# MAIN_CTRL_MMR_MAIN_CTRL_MMR_CFG0_00100000h register map
Vendor: Texas Instruments
Registers are 32-bit, read-write, reset 0x0 unless marked. A register's access mark holds for its fields unless they carry their own. Offsets are as the file gives them; [hi:lo] are bit positions; {n}, {i} and the like mark numbered series.

## MAIN_CTRL_MMR_CFG0 (part 2 of 2)
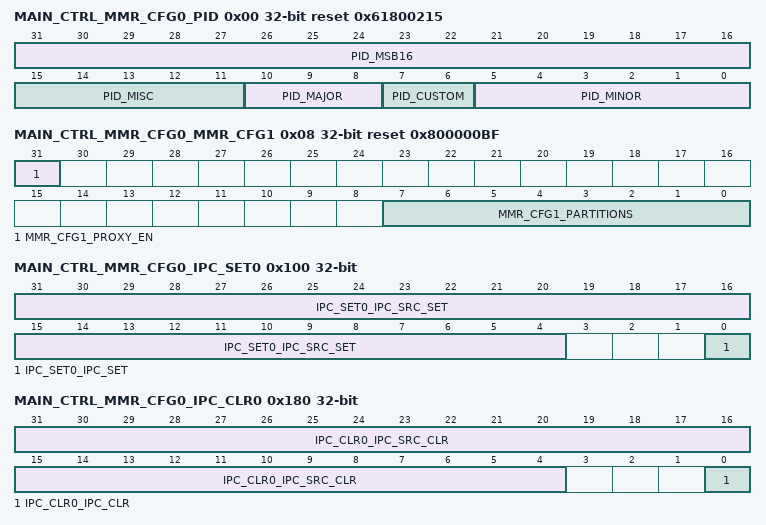
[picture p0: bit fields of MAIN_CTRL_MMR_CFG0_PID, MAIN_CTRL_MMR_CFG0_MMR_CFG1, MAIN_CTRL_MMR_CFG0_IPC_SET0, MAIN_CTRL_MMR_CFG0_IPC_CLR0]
0x00 MAIN_CTRL_MMR_CFG0_PID ro reset 0x61800215
  [31:16] PID_MSB16 — Reset Source: mod_g_rst_n
  [15:11] PID_MISC — Reset Source: mod_g_rst_n
  [10:8] PID_MAJOR — Reset Source: mod_g_rst_n
  [7:6] PID_CUSTOM — Reset Source: mod_g_rst_n
  [5:0] PID_MINOR — Reset Source: mod_g_rst_n
0x08 MAIN_CTRL_MMR_CFG0_MMR_CFG1 ro reset 0x800000BF
  [31] MMR_CFG1_PROXY_EN — Proxy addressing activated Reset Source: mod_por_rst_n
  [7:0] MMR_CFG1_PARTITIONS — Indicates present partitions Reset Source: mod_por_rst_n
0x100 MAIN_CTRL_MMR_CFG0_IPC_SET0 access not given
  [31:4] IPC_SET0_IPC_SRC_SET — Read returns current valueWrite: 0 - No effect 1 - Sets both corresponding IPC_CLR and the IPC_SET bits Reset Source: mod_g_rst_n (access R/W1TS)
  [0] IPC_SET0_IPC_SET — Read returns 0Write: 0 - No effect 1 - Sets both corresponding IPC_CLR and the IPC_SET bits Reset Source: mod_g_rst_n (access R/W1TS)
0x180 MAIN_CTRL_MMR_CFG0_IPC_CLR0 access not given
  [31:4] IPC_CLR0_IPC_SRC_CLR — Read returns current valueWrite: 0 - No effect 1 - Clears both corresponding IPC_CLR and the IPC_SET bits Reset Source: mod_g_rst_n (access R/W1TC)
  [0] IPC_CLR0_IPC_CLR — Read returns current valueWrite: 0 - No effect 1 - Clears both corresponding IPC_CLR and the IPC_SET bits Reset Source: mod_g_rst_n (access R/W1TC)
{0x1008+0x4000*i} MAIN_CTRL_MMR_CFG0_LOCK{i}_KICK0 (i=0..2)
  [31:0] LOCK{i}_KICK0 — - KICK0 component Reset Source: mod_g_rst_n
{0x100C+0x4000*i} MAIN_CTRL_MMR_CFG0_LOCK{i}_KICK1 (i=0..2)
  [31:0] LOCK{i}_KICK1 — - KICK1 component Reset Source: mod_g_rst_n
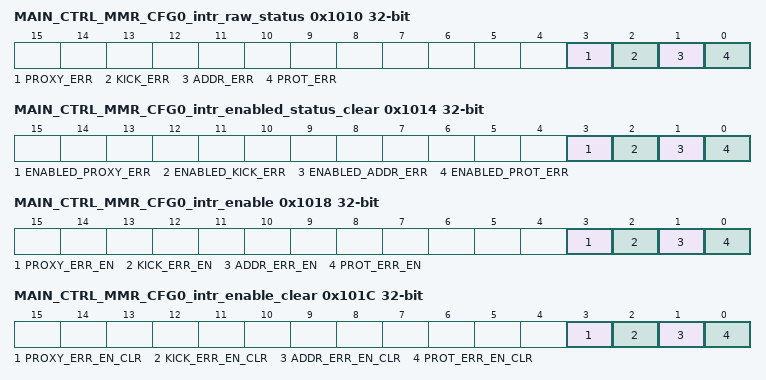
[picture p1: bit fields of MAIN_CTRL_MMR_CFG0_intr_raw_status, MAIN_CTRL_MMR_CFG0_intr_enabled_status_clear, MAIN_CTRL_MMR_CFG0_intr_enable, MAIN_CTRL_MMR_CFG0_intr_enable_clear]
0x1010 MAIN_CTRL_MMR_CFG0_intr_raw_status access not given
  [3] PROXY_ERR — Proxy0 access violation error. Raw status is read. Write a 1 to set the status. Writing a 0 has no effect. Reset Source: mod_g_rst_n (access R/W1TS)
  [2] KICK_ERR — Kick access violation error. Raw status is read. Write a 1 to set the status. Writing a 0 has no effect. Reset Source: mod_g_rst_n (access R/W1TS)
  [1] ADDR_ERR — Addressing violation error. Raw status is read. Write a 1 to set the status. Writing a 0 has no effect. Reset Source: mod_g_rst_n (access R/W1TS)
  [0] PROT_ERR — Protection violation error. Raw status is read. Write a 1 to set the status. Writing a 0 has no effect. Reset Source: mod_g_rst_n (access R/W1TS)
0x1014 MAIN_CTRL_MMR_CFG0_intr_enabled_status_clear access not given
  [3] ENABLED_PROXY_ERR — Proxy0 access violation error. Enabled status is read. Write a 1 to clear the status. Writing a 0 has no effect. Reset Source: mod_g_rst_n (access R/W1TC)
  [2] ENABLED_KICK_ERR — Kick access violation error. Enabled status is read. Write a 1 to clear the status. Writing a 0 has no effect. Reset Source: mod_g_rst_n (access R/W1TC)
  [1] ENABLED_ADDR_ERR — Addressing violation error. Enabled status is read. Write a 1 to clear the status. Writing a 0 has no effect. Reset Source: mod_g_rst_n (access R/W1TC)
  [0] ENABLED_PROT_ERR — Protection violation error. Enabled status is read. Write a 1 to clear the status. Writing a 0 has no effect. Reset Source: mod_g_rst_n (access R/W1TC)
0x1018 MAIN_CTRL_MMR_CFG0_intr_enable access not given
  [3] PROXY_ERR_EN — Proxy0 access violation error enable. Write a 1 to set the enable. Writing a 0 has no effect. Reset Source: mod_g_rst_n (access R/W1TS)
  [2] KICK_ERR_EN — Kick access violation error enable. Write a 1 to set the enable. Writing a 0 has no effect. Reset Source: mod_g_rst_n (access R/W1TS)
  [1] ADDR_ERR_EN — Addressing violation error enable. Write a 1 to set the enable. Writing a 0 has no effect. Reset Source: mod_g_rst_n (access R/W1TS)
  [0] PROT_ERR_EN — Protection violation error enable. Write a 1 to set the enable. Writing a 0 has no effect. Reset Source: mod_g_rst_n (access R/W1TS)
0x101C MAIN_CTRL_MMR_CFG0_intr_enable_clear access not given
  [3] PROXY_ERR_EN_CLR — Proxy0 access violation error enable clear. Write a 1 to clear the enable. Writing a 0 has no effect. Reset Source: mod_g_rst_n (access R/W1TC)
  [2] KICK_ERR_EN_CLR — Kick access violation error enable clear. Write a 1 to clear the enable. Writing a 0 has no effect. Reset Source: mod_g_rst_n (access R/W1TC)
  [1] ADDR_ERR_EN_CLR — Addressing violation error enable clear. Write a 1 to clear the enable. Writing a 0 has no effect. Reset Source: mod_g_rst_n (access R/W1TC)
  [0] PROT_ERR_EN_CLR — Protection violation error enable clear. Write a 1 to clear the enable. Writing a 0 has no effect. Reset Source: mod_g_rst_n (access R/W1TC)
0x1020 MAIN_CTRL_MMR_CFG0_eoi
  [7:0] EOI_VECTOR — EOI vector value. Write this with interrupt distribution value in the chip. Reset Source: mod_g_rst_n
0x1024 MAIN_CTRL_MMR_CFG0_fault_address ro
  [31:0] FAULT_ADDR — Fault Address. Reset Source: mod_g_rst_n
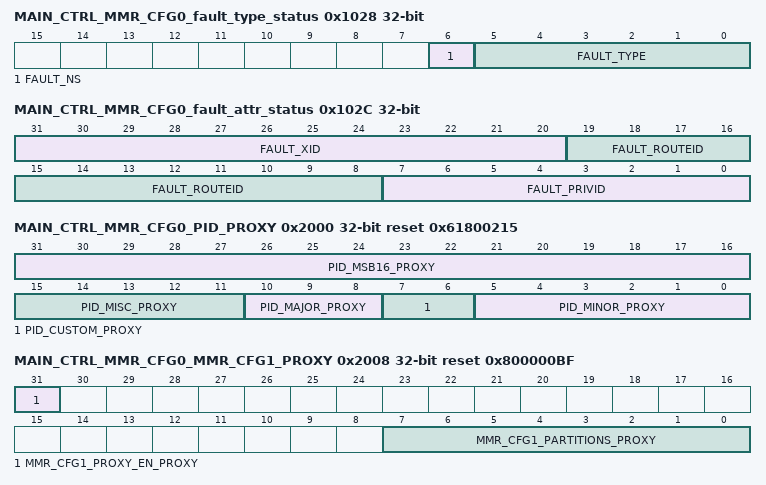
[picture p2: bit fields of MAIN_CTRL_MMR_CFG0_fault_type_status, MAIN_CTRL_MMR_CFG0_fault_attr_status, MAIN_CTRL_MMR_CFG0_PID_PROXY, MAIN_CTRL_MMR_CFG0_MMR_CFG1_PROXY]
0x1028 MAIN_CTRL_MMR_CFG0_fault_type_status ro
  [6] FAULT_NS — Non-secure access. Reset Source: mod_g_rst_n
  [5:0] FAULT_TYPE — Fault Type 10_0000 = Supervisor read fault - priv = 1 dir = 1 dtype != 1 01_0000 = Supervisor write fault - priv = 1 dir = 0 00_1000 = Supervisor execute fault - priv = 1 dir = 1 dtype = 1 00_0100 = User read fault - priv = 0 dir = 1 dtype = 1 00_0010 = User write fault - priv = 0 dir = 0 00_0001 = User execute fault - priv = 0 dir = 1 dtype = 1 00_0000 = No fault Reset Source: mod_g_rst_n
0x102C MAIN_CTRL_MMR_CFG0_fault_attr_status ro
  [31:20] FAULT_XID — XID. Reset Source: mod_g_rst_n
  [19:8] FAULT_ROUTEID — Route ID. Reset Source: mod_g_rst_n
  [7:0] FAULT_PRIVID — Privilege ID. Reset Source: mod_g_rst_n
0x1030 MAIN_CTRL_MMR_CFG0_fault_clear wo
  [0] FAULT_CLR — Fault clear. Writing a 1 clears the current fault. Writing a 0 has no effect. Reset Source: mod_g_rst_n
{0x1100+4i} MAIN_CTRL_MMR_CFG0_CLAIMREG_P0_R{i}_READONLY ro (i=0..6)
  [31:0] CLAIMREG_P0_R{i}_READONLY — Claim bits for Partition 0 Reset Source: mod_g_rst_n
0x2000 MAIN_CTRL_MMR_CFG0_PID_PROXY ro reset 0x61800215
  [31:16] PID_MSB16_PROXY — Reset Source: mod_g_rst_n
  [15:11] PID_MISC_PROXY — Reset Source: mod_g_rst_n
  [10:8] PID_MAJOR_PROXY — Reset Source: mod_g_rst_n
  [7:6] PID_CUSTOM_PROXY — Reset Source: mod_g_rst_n
  [5:0] PID_MINOR_PROXY — Reset Source: mod_g_rst_n
0x2008 MAIN_CTRL_MMR_CFG0_MMR_CFG1_PROXY ro reset 0x800000BF
  [31] MMR_CFG1_PROXY_EN_PROXY — Proxy addressing activated Reset Source: mod_por_rst_n
  [7:0] MMR_CFG1_PARTITIONS_PROXY — Indicates present partitions Reset Source: mod_por_rst_n
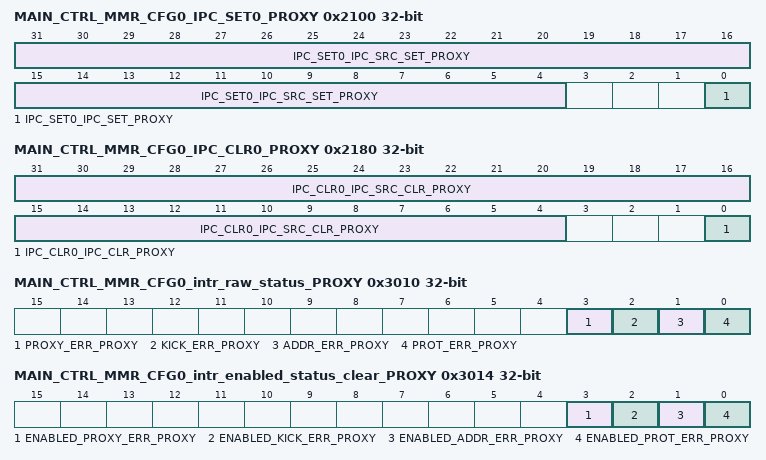
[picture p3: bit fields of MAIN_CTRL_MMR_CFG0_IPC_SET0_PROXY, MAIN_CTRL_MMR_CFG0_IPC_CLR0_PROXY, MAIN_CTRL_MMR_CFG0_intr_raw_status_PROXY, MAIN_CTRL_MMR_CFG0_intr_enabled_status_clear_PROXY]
0x2100 MAIN_CTRL_MMR_CFG0_IPC_SET0_PROXY access not given
  [31:4] IPC_SET0_IPC_SRC_SET_PROXY — Read returns current valueWrite: 0 - No effect 1 - Sets both corresponding IPC_CLR and the IPC_SET bits Reset Source: mod_g_rst_n (access R/W1TS)
  [0] IPC_SET0_IPC_SET_PROXY — Read returns 0Write: 0 - No effect 1 - Sets both corresponding IPC_CLR and the IPC_SET bits Reset Source: mod_g_rst_n (access R/W1TS)
0x2180 MAIN_CTRL_MMR_CFG0_IPC_CLR0_PROXY access not given
  [31:4] IPC_CLR0_IPC_SRC_CLR_PROXY — Read returns current valueWrite: 0 - No effect 1 - Clears both corresponding IPC_CLR and the IPC_SET bits Reset Source: mod_g_rst_n (access R/W1TC)
  [0] IPC_CLR0_IPC_CLR_PROXY — Read returns current valueWrite: 0 - No effect 1 - Clears both corresponding IPC_CLR and the IPC_SET bits Reset Source: mod_g_rst_n (access R/W1TC)
{0x3008+0x4000*i} MAIN_CTRL_MMR_CFG0_LOCK{i}_KICK0_PROXY (i=0..2)
  [31:0] LOCK{i}_KICK0_PROXY — - KICK0 component Reset Source: mod_g_rst_n
{0x300C+0x4000*i} MAIN_CTRL_MMR_CFG0_LOCK{i}_KICK1_PROXY (i=0..2)
  [31:0] LOCK{i}_KICK1_PROXY — - KICK1 component Reset Source: mod_g_rst_n
0x3010 MAIN_CTRL_MMR_CFG0_intr_raw_status_PROXY access not given
  [3] PROXY_ERR_PROXY — Proxy0 access violation error. Raw status is read. Write a 1 to set the status. Writing a 0 has no effect. Reset Source: mod_g_rst_n (access R/W1TS)
  [2] KICK_ERR_PROXY — Kick access violation error. Raw status is read. Write a 1 to set the status. Writing a 0 has no effect. Reset Source: mod_g_rst_n (access R/W1TS)
  [1] ADDR_ERR_PROXY — Addressing violation error. Raw status is read. Write a 1 to set the status. Writing a 0 has no effect. Reset Source: mod_g_rst_n (access R/W1TS)
  [0] PROT_ERR_PROXY — Protection violation error. Raw status is read. Write a 1 to set the status. Writing a 0 has no effect. Reset Source: mod_g_rst_n (access R/W1TS)
0x3014 MAIN_CTRL_MMR_CFG0_intr_enabled_status_clear_PROXY access not given
  [3] ENABLED_PROXY_ERR_PROXY — Proxy0 access violation error. Enabled status is read. Write a 1 to clear the status. Writing a 0 has no effect. Reset Source: mod_g_rst_n (access R/W1TC)
  [2] ENABLED_KICK_ERR_PROXY — Kick access violation error. Enabled status is read. Write a 1 to clear the status. Writing a 0 has no effect. Reset Source: mod_g_rst_n (access R/W1TC)
  [1] ENABLED_ADDR_ERR_PROXY — Addressing violation error. Enabled status is read. Write a 1 to clear the status. Writing a 0 has no effect. Reset Source: mod_g_rst_n (access R/W1TC)
  [0] ENABLED_PROT_ERR_PROXY — Protection violation error. Enabled status is read. Write a 1 to clear the status. Writing a 0 has no effect. Reset Source: mod_g_rst_n (access R/W1TC)
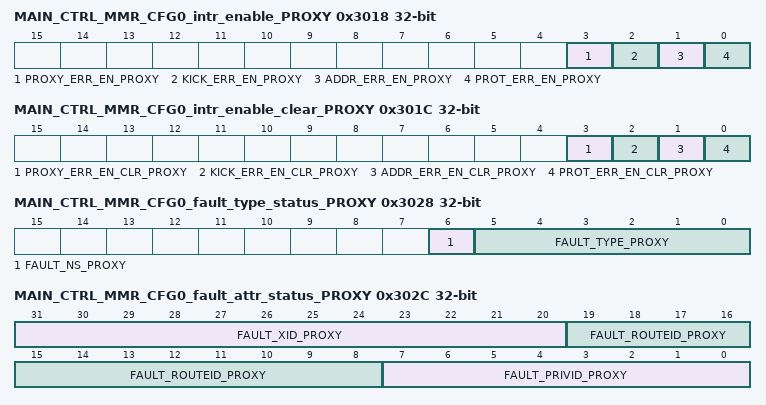
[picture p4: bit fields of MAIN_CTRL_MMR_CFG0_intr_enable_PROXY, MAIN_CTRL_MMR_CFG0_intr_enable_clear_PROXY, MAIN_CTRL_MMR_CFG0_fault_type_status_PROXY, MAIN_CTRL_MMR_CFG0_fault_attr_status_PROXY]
0x3018 MAIN_CTRL_MMR_CFG0_intr_enable_PROXY access not given
  [3] PROXY_ERR_EN_PROXY — Proxy0 access violation error enable. Write a 1 to set the enable. Writing a 0 has no effect. Reset Source: mod_g_rst_n (access R/W1TS)
  [2] KICK_ERR_EN_PROXY — Kick access violation error enable. Write a 1 to set the enable. Writing a 0 has no effect. Reset Source: mod_g_rst_n (access R/W1TS)
  [1] ADDR_ERR_EN_PROXY — Addressing violation error enable. Write a 1 to set the enable. Writing a 0 has no effect. Reset Source: mod_g_rst_n (access R/W1TS)
  [0] PROT_ERR_EN_PROXY — Protection violation error enable. Write a 1 to set the enable. Writing a 0 has no effect. Reset Source: mod_g_rst_n (access R/W1TS)
0x301C MAIN_CTRL_MMR_CFG0_intr_enable_clear_PROXY access not given
  [3] PROXY_ERR_EN_CLR_PROXY — Proxy0 access violation error enable clear. Write a 1 to clear the enable. Writing a 0 has no effect. Reset Source: mod_g_rst_n (access R/W1TC)
  [2] KICK_ERR_EN_CLR_PROXY — Kick access violation error enable clear. Write a 1 to clear the enable. Writing a 0 has no effect. Reset Source: mod_g_rst_n (access R/W1TC)
  [1] ADDR_ERR_EN_CLR_PROXY — Addressing violation error enable clear. Write a 1 to clear the enable. Writing a 0 has no effect. Reset Source: mod_g_rst_n (access R/W1TC)
  [0] PROT_ERR_EN_CLR_PROXY — Protection violation error enable clear. Write a 1 to clear the enable. Writing a 0 has no effect. Reset Source: mod_g_rst_n (access R/W1TC)
0x3020 MAIN_CTRL_MMR_CFG0_eoi_PROXY
  [7:0] EOI_VECTOR_PROXY — EOI vector value. Write this with interrupt distribution value in the chip. Reset Source: mod_g_rst_n
0x3024 MAIN_CTRL_MMR_CFG0_fault_address_PROXY ro
  [31:0] FAULT_ADDR_PROXY — Fault Address. Reset Source: mod_g_rst_n
0x3028 MAIN_CTRL_MMR_CFG0_fault_type_status_PROXY ro
  [6] FAULT_NS_PROXY — Non-secure access. Reset Source: mod_g_rst_n
  [5:0] FAULT_TYPE_PROXY — Fault Type 10_0000 = Supervisor read fault - priv = 1 dir = 1 dtype != 1 01_0000 = Supervisor write fault - priv = 1 dir = 0 00_1000 = Supervisor execute fault - priv = 1 dir = 1 dtype = 1 00_0100 = User read fault - priv = 0 dir = 1 dtype = 1 00_0010 = User write fault - priv = 0 dir = 0 00_0001 = User execute fault - priv = 0 dir = 1 dtype = 1 00_0000 = No fault Reset Source: mod_g_rst_n
0x302C MAIN_CTRL_MMR_CFG0_fault_attr_status_PROXY ro
  [31:20] FAULT_XID_PROXY — XID. Reset Source: mod_g_rst_n
  [19:8] FAULT_ROUTEID_PROXY — Route ID. Reset Source: mod_g_rst_n
  [7:0] FAULT_PRIVID_PROXY — Privilege ID. Reset Source: mod_g_rst_n
0x3030 MAIN_CTRL_MMR_CFG0_fault_clear_PROXY wo
  [0] FAULT_CLR_PROXY — Fault clear. Writing a 1 clears the current fault. Writing a 0 has no effect. Reset Source: mod_g_rst_n
{0x3100+4i} MAIN_CTRL_MMR_CFG0_CLAIMREG_P0_R{i} (i=0..6)
  [31:0] CLAIMREG_P0_R{i} — Claim bits for Partition 0 Reset Source: mod_g_rst_n
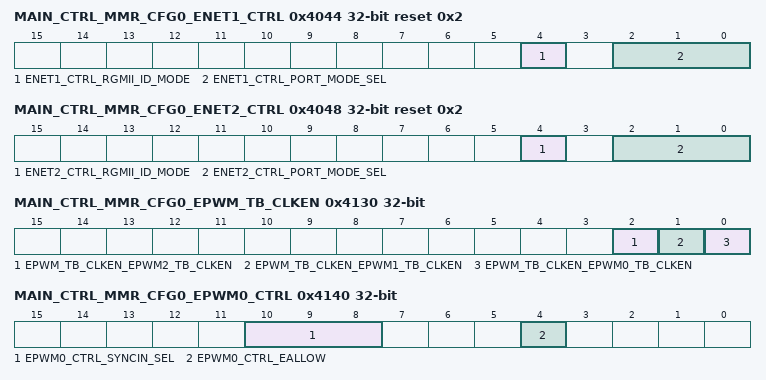
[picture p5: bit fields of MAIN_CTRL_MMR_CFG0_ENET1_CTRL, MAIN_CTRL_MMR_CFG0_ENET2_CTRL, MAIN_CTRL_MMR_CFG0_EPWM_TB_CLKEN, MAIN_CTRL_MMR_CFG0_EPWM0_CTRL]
0x4044 MAIN_CTRL_MMR_CFG0_ENET1_CTRL reset 0x2
  [4] ENET1_CTRL_RGMII_ID_MODE — Port1 RGMII internal transmit delay selection 0 - Internal transmit delay 1 - No intenal transmit delay Reset Source: sys_por_rst_n
  [2:0] ENET1_CTRL_PORT_MODE_SEL — Selects Ethernet switch Port1 interface Field values (others are reserved):3'b000 - GMII/MII (not supported)3'b001 - RMII3'b010 - RGMII3'b011 - SGMII (not supported)3'b100 - QSGMII (not supported)3'b101 - XFI (not supported)3'b110 - QSGMII_SUB (not supported)3'b111 - Reserved Reset Source: sys_por_rst_n
0x4048 MAIN_CTRL_MMR_CFG0_ENET2_CTRL reset 0x2
  [4] ENET2_CTRL_RGMII_ID_MODE — Port2 RGMII internal transmit delay selection 0 - Internal transmit delay 1 - No intenal transmit delay Reset Source: sys_por_rst_n
  [2:0] ENET2_CTRL_PORT_MODE_SEL — Selects Ethernet switch Port2 interface Field values (others are reserved):3'b000 - GMII/MII (not supported)3'b001 - RMII3'b010 - RGMII3'b011 - SGMII (not supported)3'b100 - QSGMII (not supported)3'b101 - XFI (not supported)3'b110 - QSGMII_SUB (not supported)3'b111 - Reserved Reset Source: sys_por_rst_n
0x4130 MAIN_CTRL_MMR_CFG0_EPWM_TB_CLKEN
  [2] EPWM_TB_CLKEN_EPWM2_TB_CLKEN — Activates Timebase Clock of EPWM2 When Set Reset Source: mod_g_rst_n
  [1] EPWM_TB_CLKEN_EPWM1_TB_CLKEN — Activates Timebase Clock of EPWM1 When Set Reset Source: mod_g_rst_n
  [0] EPWM_TB_CLKEN_EPWM0_TB_CLKEN — Activates Timebase Clock of EPWM0 When Set Reset Source: mod_g_rst_n
0x4140 MAIN_CTRL_MMR_CFG0_EPWM0_CTRL
  [10:8] EPWM0_CTRL_SYNCIN_SEL — Selects the source of the EPWM0 synchronization inputField values (others are reserved):3'b000 - EPWM0_SYNCIN Pin3'b001 - None3'b010 - Time Sync Router 193'b011 - Compare Event Router 32undefined - undefined3'b100 - None3'b101 - None3'b110 - None3'b111 - None Reset Source: mod_g_rst_n
  [4] EPWM0_CTRL_EALLOW — Activate write access to EPWM tripzone registers 0 - Deactivated 1 - Activated Reset Source: mod_g_rst_n
0x4144 MAIN_CTRL_MMR_CFG0_EPWM1_CTRL
  [4] EPWM1_CTRL_EALLOW — Activate write access to EPWM tripzone registers 0 - Deactivated 1 - Activated Reset Source: mod_g_rst_n
0x4148 MAIN_CTRL_MMR_CFG0_EPWM2_CTRL
  [4] EPWM2_CTRL_EALLOW — Activate write access to EPWM tripzone registers 0 - Deactivated 1 - Activated Reset Source: mod_g_rst_n
{0x4180+4i} MAIN_CTRL_MMR_CFG0_EQEP{i}_CTRL (i=0..2)
  [4:0] EQEP{i}_CTRL_SOCA_SEL — Selects the source of SOCA input for EQEP{i}Field values (others are reserved):undefined - undefinedundefined - undefined5'b00010 - EPWM SOCA_OUT5'b00011 - EPWM SOCB_OUT5'b00100 - MCU_TIMER0 PWM 5'b00101 - MCU_TIMER1 PWM 5'b00110 - MCU_TIMER2 PWM 5'b00111 - MCU_TIMER3 PWM 5'b01000 - TIMER0 PWM 5'b01001 - TIMER1 PWM 5'b01010 - TIMER2 PWM 5'b01011 - TIMER3 PWM 5'b01100 - TIMER4 PWM 5'b01101 - TIMER5 PWM 5'b01110 - TIMER6 PWM 5'b01111 - TIMER7 PWM 5'b10000 - WKUP TIMER0 PWM 5'b10001 - WKUP TIMER1 PWM Reset Source: mod_g_rst_n
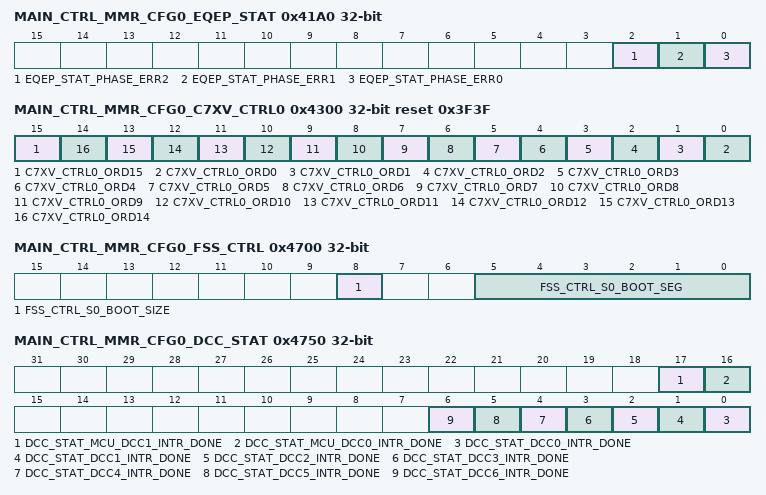
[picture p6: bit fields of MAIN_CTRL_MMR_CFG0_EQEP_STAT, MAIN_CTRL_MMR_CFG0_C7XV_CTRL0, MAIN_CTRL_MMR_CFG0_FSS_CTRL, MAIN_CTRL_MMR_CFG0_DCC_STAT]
0x41A0 MAIN_CTRL_MMR_CFG0_EQEP_STAT ro
  [2] EQEP_STAT_PHASE_ERR2 — EQEP2 Phase error status 0 - No error 1 - Phase error occurred Reset Source: mod_g_rst_n
  [1] EQEP_STAT_PHASE_ERR1 — EQEP1 Phase error status 0 - No error 1 - Phase error occurred Reset Source: mod_g_rst_n
  [0] EQEP_STAT_PHASE_ERR0 — EQEP0 Phase error status 0 - No error 1 - Phase error occurred Reset Source: mod_g_rst_n
0x4204 MAIN_CTRL_MMR_CFG0_TIMER1_CTRL
  [8] TIMER1_CTRL_CASCADE_EN — Activates cascading of TIMER1 to TIMER0 Reset Source: sys_por_rst_n
0x420C MAIN_CTRL_MMR_CFG0_TIMER3_CTRL
  [8] TIMER3_CTRL_CASCADE_EN — Activates cascading of TIMER3 to TIMER2 Reset Source: sys_por_rst_n
0x4214 MAIN_CTRL_MMR_CFG0_TIMER5_CTRL
  [8] TIMER5_CTRL_CASCADE_EN — Activates cascading of TIMER5 to TIMER4 Reset Source: sys_por_rst_n
0x421C MAIN_CTRL_MMR_CFG0_TIMER7_CTRL
  [8] TIMER7_CTRL_CASCADE_EN — Activates cascading of TIMER7 to TIMER6 Reset Source: sys_por_rst_n
0x4300 MAIN_CTRL_MMR_CFG0_C7XV_CTRL0 reset 0x3F3F
  [15] C7XV_CTRL0_ORD15 — Ordering Rule for Order ID 15 Field values (others are reserved):1'b1 - RELAXED_R_TO_W1'b0 - RELAXED_READ Reset Source: mod_por_rst_n
  [n] C7XV_CTRL0_ORD{n} (n=0..14) — Ordering Rule for Order ID {n}Field values (others are reserved):1'b1 - RELAXED_R_TO_W1'b0 - RELAXED_READ Reset Source: mod_por_rst_n
{0x44C0+4i} MAIN_CTRL_MMR_CFG0_EMMC{i}_STAT ro (i=0..2)
  [0] EMMC{i}_STAT_SIG1P8_EN — Status of 1.8V Signal Activate from EMMC{i} Module Reset Source: mod_g_rst_n
0x4700 MAIN_CTRL_MMR_CFG0_FSS_CTRL
  [8] FSS_CTRL_S0_BOOT_SIZE — Selects the size of the boot block to be used for the S0 (OSPI0) flash interface 0 - S0 boot size is 64 MB 1 - S0 boot size is 128 MB Reset Source: mod_g_rst_n
  [5:0] FSS_CTRL_S0_BOOT_SEG — Selects the boot block to be used for the S0 (OSPI0) flash interface. If the s0_boot_size is 128 MB then only bits [4:0] of this field are used. Care must be taken to account for the address translation as to not fall off or wrap the address of the flash. (e.g. if both ECC and authentication are activated for 64 MB boot, the highest valid block number is is 49, as sector 50 is only .2M Bytes in size.) 6'h00 - Use block 0 6'h01 - Use block 1 : 6'h3F - Use block 63 Reset Source: mod_g_rst_n
0x4750 MAIN_CTRL_MMR_CFG0_DCC_STAT ro
  [17] DCC_STAT_MCU_DCC1_INTR_DONE — MCU_DCC1 Done Interrupt Status0 = No Interrupt Pending1 = Interrupt Pending Reset Source: mod_g_rst_n
  [16] DCC_STAT_MCU_DCC0_INTR_DONE — MCU_DCC0 Done Interrupt Status0 = No Interrupt Pending1 = Interrupt Pending Reset Source: mod_g_rst_n
  [n] DCC_STAT_DCC{n}_INTR_DONE (n=0..6) — DCC{n} Done Interrupt Status0 = No Interrupt Pending1 = Interrupt Pending Reset Source: mod_g_rst_n
{0x5100+4i} MAIN_CTRL_MMR_CFG0_CLAIMREG_P1_R{i}_READONLY ro (i=0..14)
  [31:0] CLAIMREG_P1_R{i}_READONLY — Claim bits for Partition 1 Reset Source: mod_g_rst_n
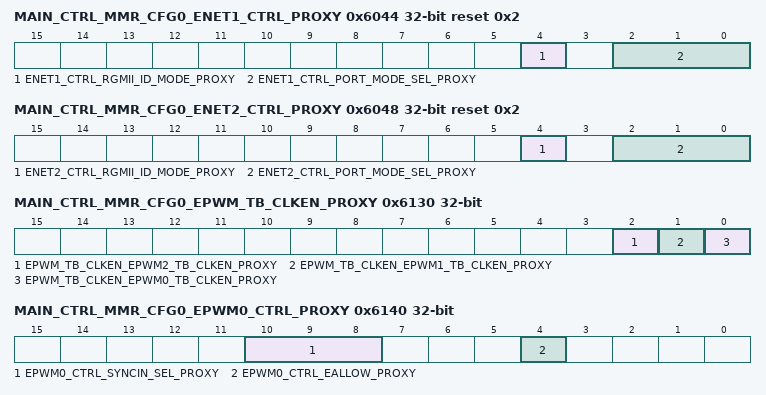
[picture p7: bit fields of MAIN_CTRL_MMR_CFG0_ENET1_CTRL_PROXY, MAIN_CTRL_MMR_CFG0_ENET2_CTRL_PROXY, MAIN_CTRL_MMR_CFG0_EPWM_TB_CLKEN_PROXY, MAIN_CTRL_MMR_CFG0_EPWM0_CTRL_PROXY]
0x6044 MAIN_CTRL_MMR_CFG0_ENET1_CTRL_PROXY reset 0x2
  [4] ENET1_CTRL_RGMII_ID_MODE_PROXY — Port1 RGMII internal transmit delay selection 0 - Internal transmit delay 1 - No intenal transmit delay Reset Source: sys_por_rst_n
  [2:0] ENET1_CTRL_PORT_MODE_SEL_PROXY — Selects Ethernet switch Port1 interface Field values (others are reserved):3'b000 - GMII/MII (not supported)3'b001 - RMII3'b010 - RGMII3'b011 - SGMII (not supported)3'b100 - QSGMII (not supported)3'b101 - XFI (not supported)3'b110 - QSGMII_SUB (not supported)3'b111 - Reserved Reset Source: sys_por_rst_n
0x6048 MAIN_CTRL_MMR_CFG0_ENET2_CTRL_PROXY reset 0x2
  [4] ENET2_CTRL_RGMII_ID_MODE_PROXY — Port2 RGMII internal transmit delay selection 0 - Internal transmit delay 1 - No intenal transmit delay Reset Source: sys_por_rst_n
  [2:0] ENET2_CTRL_PORT_MODE_SEL_PROXY — Selects Ethernet switch Port2 interface Field values (others are reserved):3'b000 - GMII/MII (not supported)3'b001 - RMII3'b010 - RGMII3'b011 - SGMII (not supported)3'b100 - QSGMII (not supported)3'b101 - XFI (not supported)3'b110 - QSGMII_SUB (not supported)3'b111 - Reserved Reset Source: sys_por_rst_n
0x6130 MAIN_CTRL_MMR_CFG0_EPWM_TB_CLKEN_PROXY
  [2] EPWM_TB_CLKEN_EPWM2_TB_CLKEN_PROXY — Activates Timebase Clock of EPWM2 When Set Reset Source: mod_g_rst_n
  [1] EPWM_TB_CLKEN_EPWM1_TB_CLKEN_PROXY — Activates Timebase Clock of EPWM1 When Set Reset Source: mod_g_rst_n
  [0] EPWM_TB_CLKEN_EPWM0_TB_CLKEN_PROXY — Activates Timebase Clock of EPWM0 When Set Reset Source: mod_g_rst_n
0x6140 MAIN_CTRL_MMR_CFG0_EPWM0_CTRL_PROXY
  [10:8] EPWM0_CTRL_SYNCIN_SEL_PROXY — Selects the source of the EPWM0 synchronization inputField values (others are reserved):3'b000 - EPWM0_SYNCIN Pin3'b001 - None3'b010 - Time Sync Router 193'b011 - Compare Event Router 32undefined - undefined3'b100 - None3'b101 - None3'b110 - None3'b111 - None Reset Source: mod_g_rst_n
  [4] EPWM0_CTRL_EALLOW_PROXY — Activate write access to EPWM tripzone registers 0 - Deactivated 1 - Activated Reset Source: mod_g_rst_n
0x6144 MAIN_CTRL_MMR_CFG0_EPWM1_CTRL_PROXY
  [4] EPWM1_CTRL_EALLOW_PROXY — Activate write access to EPWM tripzone registers 0 - Deactivated 1 - Activated Reset Source: mod_g_rst_n
0x6148 MAIN_CTRL_MMR_CFG0_EPWM2_CTRL_PROXY
  [4] EPWM2_CTRL_EALLOW_PROXY — Activate write access to EPWM tripzone registers 0 - Deactivated 1 - Activated Reset Source: mod_g_rst_n
{0x6180+4i} MAIN_CTRL_MMR_CFG0_EQEP{i}_CTRL_PROXY (i=0..2)
  [4:0] EQEP{i}_CTRL_SOCA_SEL_PROXY — Selects the source of SOCA input for EQEP{i}Field values (others are reserved):undefined - undefinedundefined - undefined5'b00010 - EPWM SOCA_OUT5'b00011 - EPWM SOCB_OUT5'b00100 - MCU_TIMER0 PWM 5'b00101 - MCU_TIMER1 PWM 5'b00110 - MCU_TIMER2 PWM 5'b00111 - MCU_TIMER3 PWM 5'b01000 - TIMER0 PWM 5'b01001 - TIMER1 PWM 5'b01010 - TIMER2 PWM 5'b01011 - TIMER3 PWM 5'b01100 - TIMER4 PWM 5'b01101 - TIMER5 PWM 5'b01110 - TIMER6 PWM 5'b01111 - TIMER7 PWM 5'b10000 - WKUP TIMER0 PWM 5'b10001 - WKUP TIMER1 PWM Reset Source: mod_g_rst_n
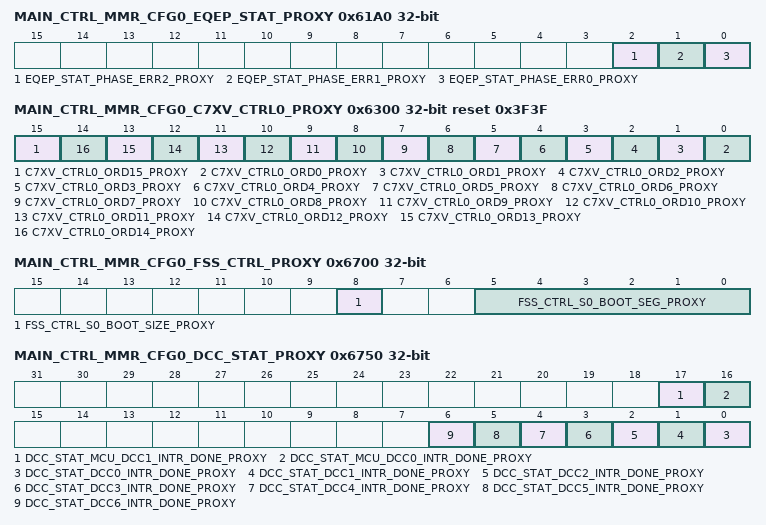
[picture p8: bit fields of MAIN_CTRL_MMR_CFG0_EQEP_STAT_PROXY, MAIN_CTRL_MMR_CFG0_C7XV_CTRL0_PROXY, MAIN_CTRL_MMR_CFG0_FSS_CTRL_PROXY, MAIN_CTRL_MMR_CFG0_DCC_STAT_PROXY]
0x61A0 MAIN_CTRL_MMR_CFG0_EQEP_STAT_PROXY ro
  [2] EQEP_STAT_PHASE_ERR2_PROXY — EQEP2 Phase error status 0 - No error 1 - Phase error occurred Reset Source: mod_g_rst_n
  [1] EQEP_STAT_PHASE_ERR1_PROXY — EQEP1 Phase error status 0 - No error 1 - Phase error occurred Reset Source: mod_g_rst_n
  [0] EQEP_STAT_PHASE_ERR0_PROXY — EQEP0 Phase error status 0 - No error 1 - Phase error occurred Reset Source: mod_g_rst_n
0x6204 MAIN_CTRL_MMR_CFG0_TIMER1_CTRL_PROXY
  [8] TIMER1_CTRL_CASCADE_EN_PROXY — Activates cascading of TIMER1 to TIMER0 Reset Source: sys_por_rst_n
0x620C MAIN_CTRL_MMR_CFG0_TIMER3_CTRL_PROXY
  [8] TIMER3_CTRL_CASCADE_EN_PROXY — Activates cascading of TIMER3 to TIMER2 Reset Source: sys_por_rst_n
0x6214 MAIN_CTRL_MMR_CFG0_TIMER5_CTRL_PROXY
  [8] TIMER5_CTRL_CASCADE_EN_PROXY — Activates cascading of TIMER5 to TIMER4 Reset Source: sys_por_rst_n
0x621C MAIN_CTRL_MMR_CFG0_TIMER7_CTRL_PROXY
  [8] TIMER7_CTRL_CASCADE_EN_PROXY — Activates cascading of TIMER7 to TIMER6 Reset Source: sys_por_rst_n
0x6300 MAIN_CTRL_MMR_CFG0_C7XV_CTRL0_PROXY reset 0x3F3F
  [15] C7XV_CTRL0_ORD15_PROXY — Ordering Rule for Order ID 15 Field values (others are reserved):1'b1 - RELAXED_R_TO_W1'b0 - RELAXED_READ Reset Source: mod_por_rst_n
  [n] C7XV_CTRL0_ORD{n}_PROXY (n=0..14) — Ordering Rule for Order ID {n}Field values (others are reserved):1'b1 - RELAXED_R_TO_W1'b0 - RELAXED_READ Reset Source: mod_por_rst_n
{0x64C0+4i} MAIN_CTRL_MMR_CFG0_EMMC{i}_STAT_PROXY ro (i=0..2)
  [0] EMMC{i}_STAT_SIG1P8_EN_PROXY — Status of 1.8V Signal Activate from EMMC{i} Module Reset Source: mod_g_rst_n
0x6700 MAIN_CTRL_MMR_CFG0_FSS_CTRL_PROXY
  [8] FSS_CTRL_S0_BOOT_SIZE_PROXY — Selects the size of the boot block to be used for the S0 (OSPI0) flash interface 0 - S0 boot size is 64 MB 1 - S0 boot size is 128 MB Reset Source: mod_g_rst_n
  [5:0] FSS_CTRL_S0_BOOT_SEG_PROXY — Selects the boot block to be used for the S0 (OSPI0) flash interface. If the s0_boot_size is 128 MB then only bits [4:0] of this field are used. Care must be taken to account for the address translation as to not fall off or wrap the address of the flash. (e.g. if both ECC and authentication are activated for 64 MB boot, the highest valid block number is is 49, as sector 50 is only .2M Bytes in size.) 6'h00 - Use block 0 6'h01 - Use block 1 : 6'h3F - Use block 63 Reset Source: mod_g_rst_n
0x6750 MAIN_CTRL_MMR_CFG0_DCC_STAT_PROXY ro
  [17] DCC_STAT_MCU_DCC1_INTR_DONE_PROXY — MCU_DCC1 Done Interrupt Status0 = No Interrupt Pending1 = Interrupt Pending Reset Source: mod_g_rst_n
  [16] DCC_STAT_MCU_DCC0_INTR_DONE_PROXY — MCU_DCC0 Done Interrupt Status0 = No Interrupt Pending1 = Interrupt Pending Reset Source: mod_g_rst_n
  [n] DCC_STAT_DCC{n}_INTR_DONE_PROXY (n=0..6) — DCC{n} Done Interrupt Status0 = No Interrupt Pending1 = Interrupt Pending Reset Source: mod_g_rst_n
{0x7100+4i} MAIN_CTRL_MMR_CFG0_CLAIMREG_P1_R{i} (i=0..14)
  [31:0] CLAIMREG_P1_R{i} — Claim bits for Partition 1 Reset Source: mod_g_rst_n
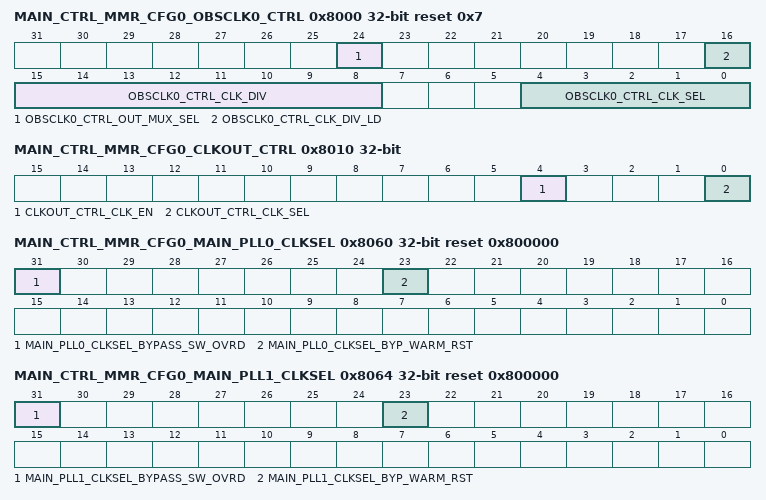
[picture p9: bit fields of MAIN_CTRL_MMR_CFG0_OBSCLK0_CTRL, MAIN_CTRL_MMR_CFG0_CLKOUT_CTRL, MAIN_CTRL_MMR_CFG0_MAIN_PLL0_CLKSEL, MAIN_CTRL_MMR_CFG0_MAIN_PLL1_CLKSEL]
0x8000 MAIN_CTRL_MMR_CFG0_OBSCLK0_CTRL reset 0x7
  [24] OBSCLK0_CTRL_OUT_MUX_SEL — OBSCLK pin output mux selection. Note, HFOSC0_CLK is a direct output from the HFOSC0, distinct from HFOSC0_CLKOUT.Note, when HFOSC0_CLK is selected (1'b1) the MCU_OBSCLK_CTRL_clk_sel field must be programmed to 5'b11111. 1'b0 - The output of the MCU_OBSCLK output divider is output on the pin 1'b1 - HFOSC0_CLK is output on the pin Reset Source: mod_por_rst_n
  [16] OBSCLK0_CTRL_CLK_DIV_LD — Load the output divider valueWriting 1 to this bit will generate a load pulse to load the OBSCLK0 divider value. This bit can be cleared but must not be set in the same write cycle in which the clk_div value is changed. Reset Source: mod_por_rst_n
  [15:8] OBSCLK0_CTRL_CLK_DIV — OBSCLK0 output dividerDivides the selected clock by clkdiv+1 for output to the OBSCLK0 pins. Supports divide by 1 to 256 (default to 1). To load the new divider value the clk_div_ld bit must be cleared and then set to 1. Reset Source: mod_por_rst_n
  [4:0] OBSCLK0_CTRL_CLK_SEL — OBSCLK0 clock source selection.Selects the source of the clock to be divided by the OBSCLK0 divider and output on the OBSCLK0 pin.Field values (others are reserved):5'b00000 - MAIN_PLL0_HSDIV0_CLKOUT5'b00001 - MAIN_PLL1_HSDIV0_CLKOUT5'b00010 - MAIN_PLL2_HSDIV0_CLKOUT5'b00011 - MAIN_PLL8_HSDIV0_CLKOUT_DIV45'b00100 - MAIN_PLL12_HSDIV0_CLKOUT_DIV45'b00101 - CLK_12M_RC5'b00110 - HFOSC0_CLKOUT_32K5'b00111 - PLLCTRL_OBSCLK5'b01000 - HFOSC0_CLKOUT5'b01001 - CLK_32K5'b01010 - cpsw2g_cpts_genf05'b01011 - cpsw2g_cpts_genf15'b01100 - MCU_PLL0_HSDIV0_CLKOUT5'b01101 - MAIN_PLL15_HSDIV0_CLKOUTundefined - undefined5'b01110 - reserved5'b01111 - MAIN_PLL17_HSDIV0_CLKOUT5'b10000 - MAIN_SYSCLK05'b10001 - DEVICE_CLKOUT_32K5'b10010 - MAIN_PLL5_HSDIV0_CLKOUT5'b10011 - MAIN_PLL7_HSDIV0_CLKOUT_DIV4 Reset Source: mod_por_rst_n
0x8010 MAIN_CTRL_MMR_CFG0_CLKOUT_CTRL
  [4] CLKOUT_CTRL_CLK_EN — (Reserved) Reset Source: mod_g_rst_n
  [0] CLKOUT_CTRL_CLK_SEL — Selects CLKOUT clock sourceField values (others are reserved):1'b0 - MAIN_PLL2_HSDIV1_CLKOUT / 51'b1 - MAIN_PLL2_HSDIV1_CLKOUT / 10 Reset Source: mod_g_rst_n
0x8060 MAIN_CTRL_MMR_CFG0_MAIN_PLL0_CLKSEL reset 0x800000
  [31] MAIN_PLL0_CLKSEL_BYPASS_SW_OVRD — PLL Bypass warm reset software overrideWhen set, activates software control of exit from bypass mode on a main_reset_z for MAIN PLL0. This bit must not be set until after the corresponding byp_warm_rst bit has been cleared or the PLL will immediately enter bypass mode. Reset Source: sys_por_rst_n
  [23] MAIN_PLL0_CLKSEL_BYP_WARM_RST — PLL bypass mode after warm reset.This bit is only valid when bypass_sw_ovrd is set to 1'b1 to activate bypass software override.This bit is set (1'b0) when a MAIN warm reset occurs to keep MAIN PLL0 from being bypassed, supporting reset isolation of the CPSW. 1'b0 = Exit bypass mode (based on MAIN PLL0_CTRL_bypass_en bit value) 1'b1 = Maintain bypass mode. Reset Source: main_chip1_rst_n
0x8064 MAIN_CTRL_MMR_CFG0_MAIN_PLL1_CLKSEL reset 0x800000
  [31] MAIN_PLL1_CLKSEL_BYPASS_SW_OVRD — PLL Bypass warm reset software overrideThis bit has no effect on PLL operation as MAIN PLL1 is reset isolated and exit from bypass mode (in the case of a Thermal reset) is always hardware controlled. Reset Source: sys_por_rst_n
  [23] MAIN_PLL1_CLKSEL_BYP_WARM_RST — PLL bypass mode after warm reset.This bit is cleared to 1'b0 when a MAIN warm reset occurs which will cause MAIN PLL1 to exit bypass mode after reset exit. Setting this bit will have no effect on PLL behaviot. Because MAIN PLL1 is warm reset insensitive, bypass mode will only be entered (and exited) in the case of a Thermal reset event. Reset Source: main_chip1_rst_n
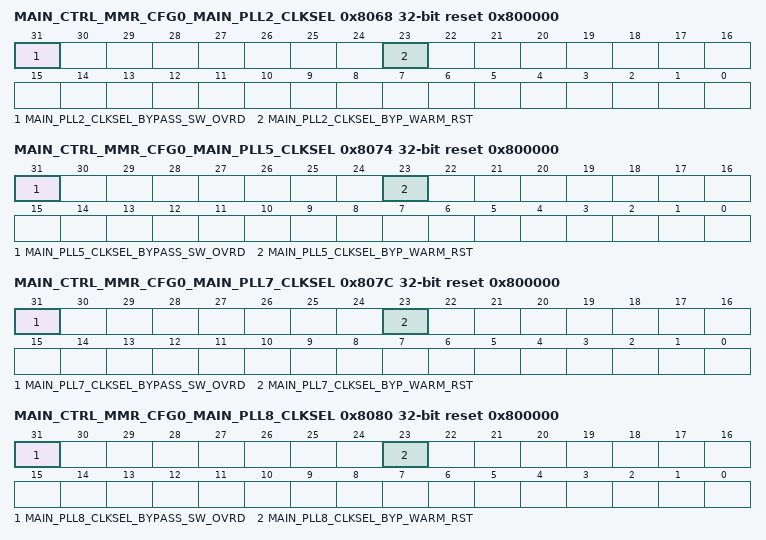
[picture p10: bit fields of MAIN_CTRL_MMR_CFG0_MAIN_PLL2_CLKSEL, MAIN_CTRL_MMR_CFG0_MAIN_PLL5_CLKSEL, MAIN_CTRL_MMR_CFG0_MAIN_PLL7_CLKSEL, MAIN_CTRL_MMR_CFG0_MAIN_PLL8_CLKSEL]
0x8068 MAIN_CTRL_MMR_CFG0_MAIN_PLL2_CLKSEL reset 0x800000
  [31] MAIN_PLL2_CLKSEL_BYPASS_SW_OVRD — PLL Bypass warm reset software overrideThis bit has no effect on PLL operation as MAIN PLL2 is reset isolated and exit from bypass mode (in the case of a Thermal reset) is always hardware controlled. Reset Source: sys_por_rst_n
  [23] MAIN_PLL2_CLKSEL_BYP_WARM_RST — PLL bypass mode after warm reset.This bit is cleared to 1'b0 when a MAIN warm reset occurs which will cause MAIN PLL2 to exit bypass mode after reset exit. Setting this bit will have no effect on PLL behaviot. Because MAIN PLL2 is warm reset insensitive, bypass mode will only be entered (and exited) in the case of a Thermal reset event. Reset Source: main_chip1_rst_n
0x8074 MAIN_CTRL_MMR_CFG0_MAIN_PLL5_CLKSEL reset 0x800000
  [31] MAIN_PLL5_CLKSEL_BYPASS_SW_OVRD — PLL Bypass warm reset software overrideWhen set, activates software control of exit from bypass mode on a main_reset_z for MAIN PLL5. This bit must not be set until after the corresponding byp_warm_rst bit has been cleared or the PLL will immediately enter bypass mode. Reset Source: sys_por_rst_n
  [23] MAIN_PLL5_CLKSEL_BYP_WARM_RST — PLL bypass mode after warm reset.This bit is only valid when bypass_sw_ovrd is set to 1'b1 to activate bypass software override.This bit is set (1'b1) when a MAIN warm reset occurs and will keep MAIN PLL5 in bypass mode after reset exit until cleared by software. 1'b0 = Exit bypass mode (based on MAIN PLL5_CTRL_bypass_en bit value) 1'b1 = Maintain bypass mode. Reset Source: main_chip1_rst_n
0x807C MAIN_CTRL_MMR_CFG0_MAIN_PLL7_CLKSEL reset 0x800000
  [31] MAIN_PLL7_CLKSEL_BYPASS_SW_OVRD — PLL Bypass warm reset software overrideWhen set, activates software control of exit from bypass mode on a main_reset_z for MAIN PLL7. This bit must not be set until after the corresponding byp_warm_rst bit has been cleared or the PLL will immediately enter bypass mode. Reset Source: sys_por_rst_n
  [23] MAIN_PLL7_CLKSEL_BYP_WARM_RST — PLL bypass mode after warm reset.This bit is only valid when bypass_sw_ovrd is set to 1'b1 to activate bypass software override.This bit is set (1'b1) when a MAIN warm reset occurs and will keep MAIN PLL7 in bypass mode after reset exit until cleared by software. 1'b0 = Exit bypass mode (based on MAIN PLL7_CTRL_bypass_en bit value) 1'b1 = Maintain bypass mode. Reset Source: main_chip1_rst_n
0x8080 MAIN_CTRL_MMR_CFG0_MAIN_PLL8_CLKSEL reset 0x800000
  [31] MAIN_PLL8_CLKSEL_BYPASS_SW_OVRD — PLL Bypass warm reset software overrideWhen set, activates software control of exit from bypass mode on a main_reset_z for MAIN PLL8. This bit must not be set until after the corresponding byp_warm_rst bit has been cleared or the PLL will immediately enter bypass mode. Reset Source: sys_por_rst_n
  [23] MAIN_PLL8_CLKSEL_BYP_WARM_RST — PLL bypass mode after warm reset.This bit is only valid when bypass_sw_ovrd is set to 1'b1 to activate bypass software override.This bit is set (1'b1) when a MAIN warm reset occurs and will keep MAIN PLL8 in bypass mode after reset exit until cleared by software. 1'b0 = Exit bypass mode (based on MAIN PLL8_CTRL_bypass_en bit value) 1'b1 = Maintain bypass mode. Reset Source: main_chip1_rst_n
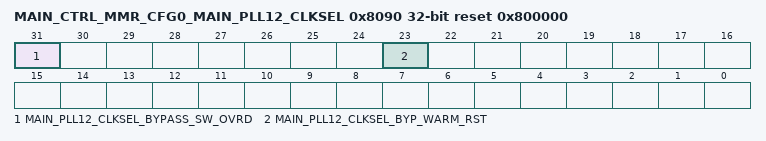
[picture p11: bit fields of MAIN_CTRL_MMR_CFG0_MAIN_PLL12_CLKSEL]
0x8090 MAIN_CTRL_MMR_CFG0_MAIN_PLL12_CLKSEL reset 0x800000
  [31] MAIN_PLL12_CLKSEL_BYPASS_SW_OVRD — PLL Bypass warm reset software overrideWhen set, activates software control of exit from bypass mode on a main_reset_z for MAIN PLL12. This bit must not be set until after the corresponding byp_warm_rst bit has been cleared or the PLL will immediately enter bypass mode. Reset Source: sys_por_rst_n
  [23] MAIN_PLL12_CLKSEL_BYP_WARM_RST — PLL bypass mode after warm reset.This bit is only valid when bypass_sw_ovrd is set to 1'b1 to activate bypass software override.This bit is set (1'b1) when a MAIN warm reset occurs and will keep MAIN PLL12 in bypass mode after reset exit until cleared by software. 1'b0 = Exit bypass mode (based on MAIN PLL12_CTRL_bypass_en bit value) 1'b1 = Maintain bypass mode. Reset Source: main_chip1_rst_n
